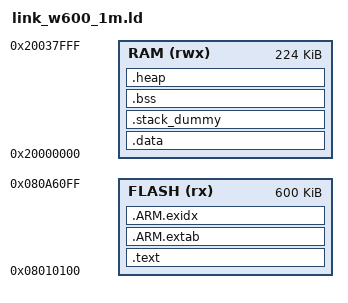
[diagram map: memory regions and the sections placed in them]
/* Linker script to configure memory regions. 
 * Need modifying for a specific board. 
 *   FLASH.ORIGIN: starting address of flash
 *   FLASH.LENGTH: length of flash
 *   RAM.ORIGIN: starting address of RAM bank 0
 *   RAM.LENGTH: length of RAM bank 0
 */
MEMORY
{
  FLASH (rx) : ORIGIN = 0x8010100, LENGTH = 600K /* 512KB-256B */
  RAM (rwx) : ORIGIN = 0x20000000, LENGTH = 0x38000 /* 224KB */
}

/* Linker script to place sections and symbol values. Should be used together
 * with other linker script that defines memory regions FLASH and RAM.
 * It references following symbols, which must be defined in code:
 *   Reset_Handler : Entry of reset handler
 * 
 * It defines following symbols, which code can use without definition:
 *   __exidx_start
 *   __exidx_end
 *   __copy_table_start__
 *   __copy_table_end__
 *   __zero_table_start__
 *   __zero_table_end__
 *   __etext
 *   __data_start__
 *   __preinit_array_start
 *   __preinit_array_end
 *   __init_array_start
 *   __init_array_end
 *   __fini_array_start
 *   __fini_array_end
 *   __data_end__
 *   __bss_start__
 *   __bss_end__
 *   __end__
 *   end
 *   __HeapLimit
 *   __StackLimit
 *   __StackTop
 *   __stack
 */
ENTRY(Reset_Handler)

SECTIONS
{
	.text :
	{
		KEEP(*(.isr_vector))
		*(.text*)

		KEEP(*(.init))
		KEEP(*(.fini))

		/* .ctors */
		*crtbegin.o(.ctors)
		*crtbegin?.o(.ctors)
		*(EXCLUDE_FILE(*crtend?.o *crtend.o) .ctors)
		*(SORT(.ctors.*))
		*(.ctors)

		/* .dtors */
 		*crtbegin.o(.dtors)
 		*crtbegin?.o(.dtors)
 		*(EXCLUDE_FILE(*crtend?.o *crtend.o) .dtors)
 		*(SORT(.dtors.*))
 		*(.dtors)

		*(.rodata*)

		KEEP(*(.eh_frame*))
	} > FLASH

	.ARM.extab : 
	{
		*(.ARM.extab* .gnu.linkonce.armextab.*)
	} > FLASH

	__exidx_start = .;
	.ARM.exidx :
	{
		*(.ARM.exidx* .gnu.linkonce.armexidx.*)
	} > FLASH
	__exidx_end = .;

	__etext = .;
		
	.data : AT (__etext)
	{
		__data_start__ = .;
		*(vtable)
		*(.data*)

		. = ALIGN(4);
		/* preinit data */
		PROVIDE_HIDDEN (__preinit_array_start = .);
		KEEP(*(.preinit_array))
		PROVIDE_HIDDEN (__preinit_array_end = .);

		. = ALIGN(4);
		/* init data */
		PROVIDE_HIDDEN (__init_array_start = .);
		KEEP(*(SORT(.init_array.*)))
		KEEP(*(.init_array))
		PROVIDE_HIDDEN (__init_array_end = .);


		. = ALIGN(4);
		/* finit data */
		PROVIDE_HIDDEN (__fini_array_start = .);
		KEEP(*(SORT(.fini_array.*)))
		KEEP(*(.fini_array))
		PROVIDE_HIDDEN (__fini_array_end = .);

		KEEP(*(.jcr*))
		. = ALIGN(4);
		/* All data end */
		__data_end__ = .;

	} > RAM
	
	.stack_dummy (COPY):
	{
		. = ALIGN(8);
		__stack_start__ = .;
		*(.stack*)
		__stack_end__ = .;
	} > RAM

	.bss __stack_end__ :
	{
		. = ALIGN(4);
		__bss_start__ = .;
		*(.bss*)
		*(COMMON)
		. = ALIGN(4);
		__bss_end__ = .;
	} > RAM 
	
	.heap (COPY):
	{
		__end__ = .;
		PROVIDE(end = .);
		*(.heap*)
		__HeapLimit = .;
	} > RAM	

	__StackTop = __stack_end__;
	__StackLimit = __StackTop - SIZEOF(.stack_dummy);
	PROVIDE(__stack = __StackTop);	
	
	ASSERT(__StackTop <= 0x20028000, "stack address error")
}

_ram_end = ORIGIN(RAM) + LENGTH(RAM);
